# pse84 register map
Vendor: Infineon Technologies; Series: PSE84; File version: 1.0
CPU: CM33 r0p1, little endian, MPU, FPU, VTOR, 3 interrupt priority bits
Registers are 32-bit, read-write, reset 0x0 unless marked. A register's access mark holds for its fields unless they carry their own. Offsets are from the block's base; [hi:lo] are bit positions; {n}, {i} and the like mark numbered series; <NAME> marks a mode.

## CRYPTO — Cryptography component
Base 0x42440000
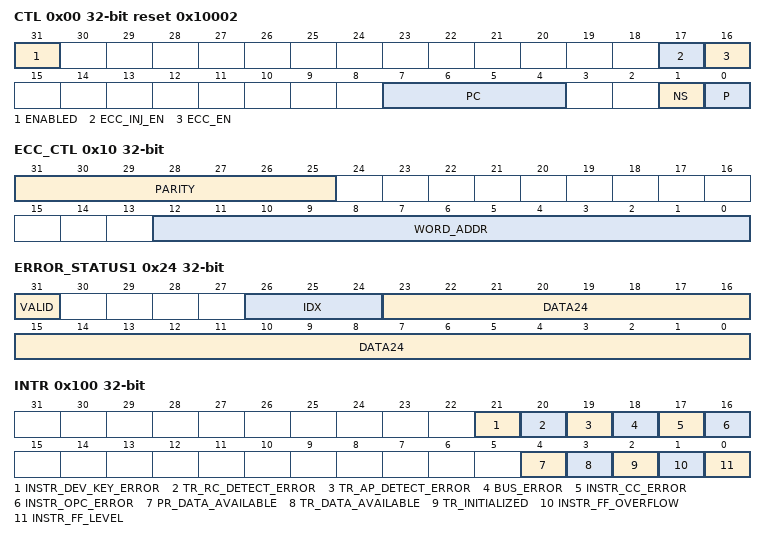
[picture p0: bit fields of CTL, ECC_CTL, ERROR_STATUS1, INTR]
0x00 CTL reset 0x10002 — Control
  [31] ENABLED — IP enable: '0': Disabled. All non-retention registers (command and status registers, instruct FIFO, internal component state machines) are reset to their default value when the IP is disabled. All retention registers retain their value when the IP is disabled. '1': Enabled. When the IP is enabled, the IP register buffer is set to '0'.
    0=DISABLED (N/A); 1=ENABLED (N/A)
  [17] ECC_INJ_EN — Enable parity injection for SRAM. When '1', the parity (ECC_CTL.PARITY) is used when a full 32-bit write is done to the ECC_CTL.WORD_ADDR word address of the SRAM.
  [16] ECC_EN — Enable ECC checking: '0': Disabled. '1': Enabled.
  [7:4] PC — Protection context. This field is set with the protection context of the transaction that writes this register; i.e. the context is inherited from the write transaction and not specified by the transaction write data. All IP master transactions use the PC field for the protection context. There is one exception: the LOAD_DEV_KEY instruction IP master transactions are always performed with protection context '0'.
  [1] NS — Secure/on-secure access control: '0': secure. '1': non-secure. This field is set with the secure/non-secure access control of the transaction that writes this register; i.e. the access control is inherited from the write transaction and not specified by the transaction write data. All IP master transactions use the NS field for the secure/non-secure access control ('hprot[4]').
  [0] P — User/privileged access control: '0': user mode. '1': privileged mode. This field is set with the user/privileged access control of the transaction that writes this register; i.e. the access control is inherited from the write transaction and not specified by the transaction write data. All IP master transactions use the P field for the user/privileged access control ('hprot[1]').
0x08 RAM_PWR_CTL reset 0x3 — SRAM power control
  [1:0] PWR_MODE — Set power mode for memory buffer SRAM.
    0=OFF (Turn OFF the SRAM. This will turn OFF both array and periphery power of the SRAM and SRAM memory contents are lost.); 1=RSVD (undefined); 2=RETAINED (Keep SRAM in Retained mode. This will turn OFF the SRAM periphery power, but array power is ON to retain memory contents. The SRAM contents will be retained in DeepSleep/DeepSleep-RAM system power mode.); 3=ENABLED (Enable SRAM for regular operation. The SRAM contents will be retained in DeepSleep/DeepSleep-RAM system power mode.)
0x0C RAM_PWR_DELAY_CTL reset 0x96 — SRAM power delay control
  [9:0] UP — Number clock cycles delay needed after power domain power up
0x10 ECC_CTL — ECC control
  [31:25] PARITY — ECC parity to use for ECC error injection at address WORD_ADDR.
  [12:0] WORD_ADDR — Specifies the word address where the parity is injected. - On a 32-bit write access to this SRAM address and when CTL.ECC_INJ_EN bit is '1', the parity (PARITY) is injected.
0x20 ERROR_STATUS0 ro reset not defined
  [31:0] DATA32 — Specifies error description information. - For INSTR_OPC_ERROR/ INSTR_CC_ERROR/ INSTR_DEV_KEY_ERROR: - Violating instruction (from instruction FIFO). - For BUS_ERROR: - Violating transfer, address.
0x24 ERROR_STATUS1 (reset mask 0x80000000)
  [31] VALID — Specifies if ERROR_STATUS0 and ERROR_STATUS1 specify valid error information. No new error information is captured as long as VALID is '1'; i.e. the error information of the first detected error is NOT overwritten.
  [26:24] IDX ro — Error source: '0': INSTR_OPC_ERROR (instruction FIFO decoder error). '1': INSTR_CC_ERROR (instruction FIFO decoder, VU CC error). '2': BUS_ERROR (bus master interface AHB-Lite bus error). '3': TR_AP_DETECT_ERROR. '4': TR_RC_DETECT_ERROR. '5': INSTR_DEV_KEY_ERROR. '6'-'7': Undefined.
  [23:0] DATA24 ro — Specifies error description information. - For BUS_ERROR: - Violating transfer, read attribute (DATA[0]). - Violating transfer, size attribute (DATA[5:4]). '0': 8-bit transfer, '1': 16 bits transfer, '2': 32-bit transfer.
0x100 INTR — Interrupt register
  [21] INSTR_DEV_KEY_ERROR — This interrupt cause is activated (HW sets the field to '1') when the LOAD_DEV_KEY instruction tries to load a device key whose DEV_KEY_ADDR_CTL.VALID or DEV_KEY_CTL.ALLOWED is set to '0'.
  [20] TR_RC_DETECT_ERROR — This interrupt cause is activated (HW sets the field to '1') when the true random number generator monitor adaptive proportion test detects a disproportionate occurrence of a specific bit value.
  [19] TR_AP_DETECT_ERROR — This interrupt cause is activated (HW sets the field to '1') when the true random number generator monitor adaptive proportion test detects a repetition of a specific bit value.
  [18] BUS_ERROR — This interrupt cause is activated (HW sets the field to '1') when a AHB-Lite bus error is observed on the AHB-Lite master interface. When the interrupt cause is activated, HW sets INSTR_FF_CTL.CLEAR to '1'.
  [17] INSTR_CC_ERROR — This interrupt cause is activated (HW sets the field to '1') when the instruction decoder encounters an instruction with a non-defined condition code. This error is only generated for VU instructions. When the interrupt cause is activated, HW sets INSTR_FF_CTL.CLEAR to '1'.
  [16] INSTR_OPC_ERROR — This interrupt cause is activated (HW sets the field to '1') when the instruction decoder encounters an instruction with a non-defined operation code (opcode). When the interrupt cause is activated, HW sets INSTR_FF_CTL.CLEAR to '1'.
  [4] PR_DATA_AVAILABLE — This interrupt cause is activated (HW sets the field to '1') when the pseudo random number generator has generated a data value.
  [3] TR_DATA_AVAILABLE — This interrupt cause is activated (HW sets the field to '1') when the true random number generator has generated a data value of the specified bit size.
  [2] TR_INITIALIZED — This interrupt cause is activated (HW sets the field to '1') when the true random number generator is initialized.
  [1] INSTR_FF_OVERFLOW — This interrupt cause is activated (HW sets the field to '1') when the instruction FIFO overflows (an attempt is made to write to a full FIFO).
  [0] INSTR_FF_LEVEL — This interrupt cause is activated (HW sets the field to '1') when the instruction FIFO event is activated.
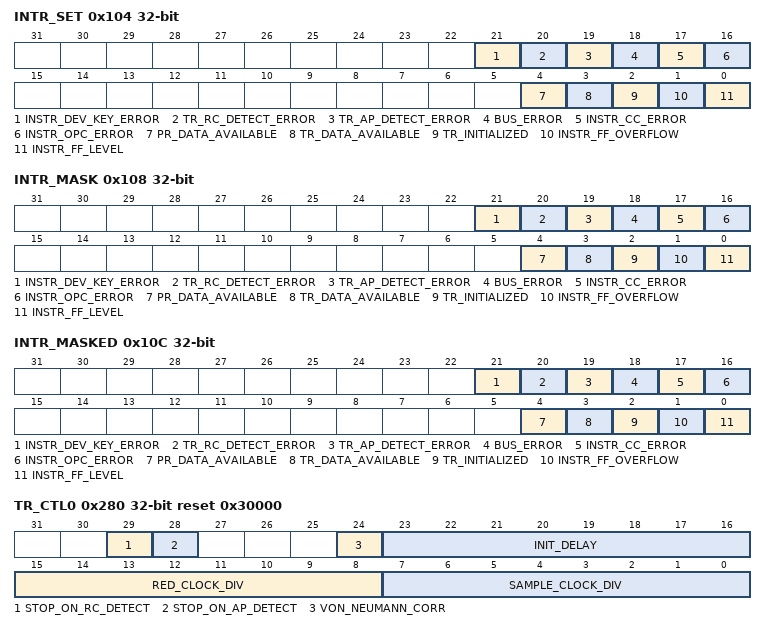
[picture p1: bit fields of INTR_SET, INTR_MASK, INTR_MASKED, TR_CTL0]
0x104 INTR_SET — Interrupt set register
  [21] INSTR_DEV_KEY_ERROR — SW writes a '1' to this field to set the corresponding field in interrupt request register.
  [20] TR_RC_DETECT_ERROR — SW writes a '1' to this field to set the corresponding field in interrupt request register.
  [19] TR_AP_DETECT_ERROR — SW writes a '1' to this field to set the corresponding field in interrupt request register.
  [18] BUS_ERROR — SW writes a '1' to this field to set the corresponding field in interrupt request register.
  [17] INSTR_CC_ERROR — SW writes a '1' to this field to set the corresponding field in interrupt request register.
  [16] INSTR_OPC_ERROR — SW writes a '1' to this field to set the corresponding field in interrupt request register.
  [4] PR_DATA_AVAILABLE — SW writes a '1' to this field to set the corresponding field in interrupt request register.
  [3] TR_DATA_AVAILABLE — SW writes a '1' to this field to set the corresponding field in interrupt request register.
  [2] TR_INITIALIZED — SW writes a '1' to this field to set the corresponding field in interrupt request register.
  [1] INSTR_FF_OVERFLOW — SW writes a '1' to this field to set the corresponding field in interrupt request register.
  [0] INSTR_FF_LEVEL — SW writes a '1' to this field to set the corresponding field in interrupt request register.
0x108 INTR_MASK — Interrupt mask register
  [21] INSTR_DEV_KEY_ERROR — Mask bit for corresponding field in interrupt request register.
  [20] TR_RC_DETECT_ERROR — Mask bit for corresponding field in interrupt request register.
  [19] TR_AP_DETECT_ERROR — Mask bit for corresponding field in interrupt request register.
  [18] BUS_ERROR — Mask bit for corresponding field in interrupt request register.
  [17] INSTR_CC_ERROR — Mask bit for corresponding field in interrupt request register.
  [16] INSTR_OPC_ERROR — Mask bit for corresponding field in interrupt request register.
  [4] PR_DATA_AVAILABLE — Mask bit for corresponding field in interrupt request register.
  [3] TR_DATA_AVAILABLE — Mask bit for corresponding field in interrupt request register.
  [2] TR_INITIALIZED — Mask bit for corresponding field in interrupt request register.
  [1] INSTR_FF_OVERFLOW — Mask bit for corresponding field in interrupt request register.
  [0] INSTR_FF_LEVEL — Mask bit for corresponding field in interrupt request register.
0x10C INTR_MASKED ro — Interrupt masked register
  [21] INSTR_DEV_KEY_ERROR — Logical and of corresponding request and mask bits.
  [20] TR_RC_DETECT_ERROR — Logical and of corresponding request and mask bits.
  [19] TR_AP_DETECT_ERROR — Logical and of corresponding request and mask bits.
  [18] BUS_ERROR — Logical and of corresponding request and mask bits.
  [17] INSTR_CC_ERROR — Logical and of corresponding request and mask bits.
  [16] INSTR_OPC_ERROR — Logical and of corresponding request and mask bits.
  [4] PR_DATA_AVAILABLE — Logical and of corresponding request and mask bits.
  [3] TR_DATA_AVAILABLE — Logical and of corresponding request and mask bits.
  [2] TR_INITIALIZED — Logical and of corresponding request and mask bits.
  [1] INSTR_FF_OVERFLOW — Logical and of corresponding request and mask bits.
  [0] INSTR_FF_LEVEL — Logical and of corresponding request and mask bits.
0x200 PR_LFSR_CTL0 reset 0xD8959BC9 — Pseudo random LFSR control 0
  [31:0] LFSR32 — State of a 32-bit Linear Feedback Shift Registers (LFSR) that is used to generate a pseudo random bit sequence. This register needs to be initialized by SW. The initialization value should be different from '0'. The three PR_LFSR_CTL registers represents the state of a 32-bit, 31-bit and 29-bit LFSR. Individually, these LFSRs generate a pseudo random bit sequence that repeats itself after (2^32)-1, (2^31)-1 and (2^29)-1 bits. The numbers (2^32)-1, (2^31)-1 and (2^29)-1 are relatively prime (their greatest common denominator is '1'). The three bit sequence are combined (XOR'd) into a single bitstream to create a pseudo random bit sequence that repeats itself after ((2^32)-1) * ((2^31)-1) * ((2*29)-1) bits. The following polynomials are used: - 32-bit irreducible polynomial: x^32+x^30+x^26+x^25+1. - 31-bit irreducible polynomial: x^31+x^28+1. - 29-bit irreducible polynomial: x^29+x^27+1.
0x204 PR_LFSR_CTL1 reset 0x2BB911F8 — Pseudo random LFSR control 1
  [30:0] LFSR31 — State of a 31-bit Linear Feedback Shift Registers (LFSR) that is used to generate a pseudo random bit sequence. See PR_LFSR_CTL0.
0x208 PR_LFSR_CTL2 reset 0x60C31B7 — Pseudo random LFSR control 2
  [28:0] LFSR29 — State of a 29-bit Linear Feedback Shift Registers (LFSR) that is used to generate a pseudo random bit sequence. See PR_LFSR_CTL0.
0x20C PR_MAX_CTL reset 0xFFFFFFFF — Pseudo random maximum control
  [31:0] DATA32 — Maximum value of to be generated random number
0x210 PR_CMD — Pseudo random command
  [0] START — Pseudo random command. On a generated number, HW sets this field to '0' and sets INTR.PR_DATA_AVAILABLE to '1.
0x218 PR_RESULT — Pseudo random result
  [31:0] DATA32 — Result of a pseudo random number generation operation. The resulting value DATA is in the range [0, PR_MAX_CTL.DATA32]. The PR_DATA_AVAILABLE interrupt cause is activated when the number is generated. Note that SW can write this field. This functionality can be used prevent information leakage.
0x280 TR_CTL0 reset 0x30000 — True random control 0
  [29] STOP_ON_RC_DETECT — Specifies if TRNG functionality is stopped on a repetition count test detection (when HW sets INTR.TR_RC_DETECT to '1'): '0': Functionality is NOT stopped. '1': Functionality is stopped (TR_CTL1 fields are set to '0' by HW).
  [28] STOP_ON_AP_DETECT — Specifies if TRNG functionality is stopped on an adaptive proportion test detection (when HW sets INTR.TR_AP_DETECT to '1'): '0': Functionality is NOT stopped. '1': Functionality is stopped (TR_CTL1 fields are set to '0' by HW).
  [24] VON_NEUMANN_CORR — Specifies if the 'von Neumann corrector' is disabled or enabled: '0': disabled. '1': enabled. The 'von Neumann corrector' post-processes the reduced bits to remove a '0' or '1' bias. The corrector operates on reduced bit pairs ('oldest bit, newest bit'): '00': no bit is produced. '01': '0' bit is produced (oldest bit). '10': '1' bit is produced (oldest bit). '11': no bit is produced. Note that the corrector produces bits at a random pace and at a frequency that is 1/4 of the reduced bit frequency (reduced bits are processed in pairs, and half of the pairs do NOT produce a bit).
  [23:16] INIT_DELAY — Specifies an initialization delay: number of removed/dropped samples before reduced bits are generated. This field should be programmed in the range [1, 255]. After starting the oscillators, at least the first 2 samples should be removed/dropped to clear the state of internal synchronizers. In addition, it is advised to drop at least the second 2 samples from the oscillators (to circumvent the semi-predictable oscillator startup behavior). This result in the default field value of '3'. Field encoding is as follows: '0': 1 sample is dropped. '1': 2 samples are dropped. ... '255': 256 samples are dropped. The TR_INITIALIZED interrupt cause is set to '1', when the initialization delay is passed.
  [15:8] RED_CLOCK_DIV — Specifies the clock divider that is used to produce reduced bits. '0': 1 reduced bit is produced for each sample. '1': 1 reduced bit is produced for each 2 samples. ... '255': 1 reduced bit is produced for each 256 samples. The reduced bits are considered random bits and shifted into TR_RESULT0.DATA32.
  [7:0] SAMPLE_CLOCK_DIV — Specifies the clock divider that is used to sample oscillator data. This clock divider is wrt. 'clk_sys'. '0': sample clock is 'clk_sys'. '1': sample clock is 'clk_sys'/2. ... '255': sample clock is 'clk_sys'/256.
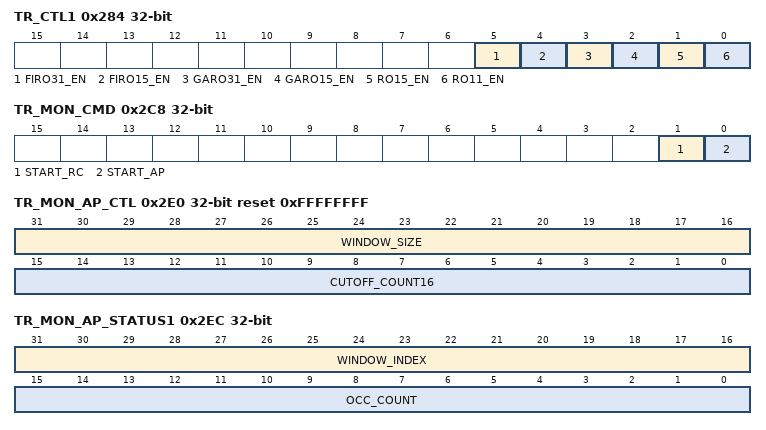
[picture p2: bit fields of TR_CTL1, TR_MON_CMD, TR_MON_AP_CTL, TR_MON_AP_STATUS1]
0x284 TR_CTL1 — True random control 1
  [5] FIRO31_EN — FW sets this field to '1' to enable the programmable Fibonacci ring oscillator with up to 31 inverters. The TR_FIRO_CTL register specifies the programmable polynomial.
  [4] FIRO15_EN — FW sets this field to '1' to enable the fixed Fibonacci ring oscillator with 15 inverters.
  [3] GARO31_EN — FW sets this field to '1' to enable the programmable Galois ring oscillator with up to 31 inverters. The TR_GARO_CTL register specifies the programmable polynomial.
  [2] GARO15_EN — FW sets this field to '1' to enable the fixed Galois ring oscillator with 15 inverters.
  [1] RO15_EN — FW sets this field to '1' to enable the ring oscillator with 15 inverters.
  [0] RO11_EN — FW sets this field to '1' to enable the ring oscillator with 11 inverters.
0x288 TR_CTL2 — True random control 2
  [5:0] SIZE — Bit size of generated random number in TR_RESULT. Legal range is in [0, 32].
0x28C TR_STATUS ro — True random status
  [0] INITIALIZED — Reflects the state of the true random number generator: '0': Not initialized (TR_CTL0.INIT_DELAY has NOT passed). '1': Initialized (TR_CTL0.INIT_DELAY has passed).
0x290 TR_CMD — True random command
  [0] START — True random command. On completion of the command, HW sets this field to '0' and sets INTR.TR_DATA_AVAILABLE to '1 when: - A random number is generated in TR_RESULT. - All ring oscillators are off (per TR_CTL1). - A repetition count (RC) or adaptive proportion (AP) error is detected during the random number generation (INTR.TR_RC/AP_DETECT_ERROR). Note: On completion of the command, SW should check TR_CTL1 and INTR.TR_RC/AP_DETECT_ERROR to ensure that no unexpected error occurred during random number generation.
0x298 TR_RESULT — True random result
  [31:0] DATA32 — Generated true random number. HW generates the number in the least significant bit positions (TR_CTL2.SIZE) of this field. The TR_DATA_AVAILABLE interrupt cause is activated when the number is generated. Note that SW can write this field. This functionality can be used prevent information leakage.
0x2A0 TR_GARO_CTL — True random GARO control
  [30:0] POLYNOMIAL31 — Polynomial for programmable Galois ring oscillator. The polynomial is represented WITHOUT the high order bit (this bit is always assumed '1'). The polynomial should be aligned such that the more significant bits (bit 30 and down) contain the polynomial and the less significant bits (bit 0 and up) contain padding '0's.
0x2A4 TR_FIRO_CTL — True random FIRO control
  [30:0] POLYNOMIAL31 — Polynomial for programmable Fibonacci ring oscillator. The polynomial is represented WITHOUT the high order bit (this bit is always assumed '1'). The polynomial should be aligned such that the more significant bits (bit 30 and down) contain the polynomial and the less significant bits (bit 0 and up) contain padding '0's.
0x2C0 TR_MON_CTL reset 0x2 — True random monitor control
  [1:0] BITSTREAM_SEL — Selection of the bitstream: '0': DAS bitstream. '1': RED bitstream. '2': TR bitstream. '3': Undefined.
0x2C8 TR_MON_CMD — True random monitor command
  [1] START_RC — Repetition count (RC) test enable: '0': Disabled. '1': Enabled. On a RC detection, HW sets this field to '0' and sets INTR.TR_RC_DETECT to '1.
  [0] START_AP — Adaptive proportion (AP) test enable: '0': Stopped. '1': Started. On a AP detection, HW sets this field to '0' and sets INTR.TR_AP_DETECT to '1.
0x2D0 TR_MON_RC_CTL reset 0xFF — True random monitor RC control
  [7:0] CUTOFF_COUNT8 — Cutoff count (legal range is [1, 255]): '0': Illegal. '1': 1 repetition. ... '255': 255 repetitions.
0x2D8 TR_MON_RC_STATUS0 ro — True random monitor RC status 0
  [0] BIT — Current active bit value: '0': '0'. '1': '1'. This field is only valid when TR_MON_RC_STATUS1.REP_COUNT is NOT equal to '0'.
0x2DC TR_MON_RC_STATUS1 ro — True random monitor RC status 1
  [7:0] REP_COUNT — Number of repetitions of the current active bit counter: '0': 0 repetitions. ... '255': 255 repetitions.
0x2E0 TR_MON_AP_CTL reset 0xFFFFFFFF — True random monitor AP control
  [31:16] WINDOW_SIZE — Window size (minus 1) : '0': 1 bit. ... '65535': 65536 bits.
  [15:0] CUTOFF_COUNT16 — Cutoff count (legal range is [1, 65535]). '0': Illegal. '1': 1 occurrence. ... '65535': 65535 occurrences.
0x2E8 TR_MON_AP_STATUS0 ro — True random monitor AP status 0
  [0] BIT — Current active bit value: '0': '0'. '1': '1'. This field is only valid when TR_MON_AP_STATUS1.OCC_COUNT is NOT equal to '0'.
0x2EC TR_MON_AP_STATUS1 ro — True random monitor AP status 1
  [31:16] WINDOW_INDEX — Counter to keep track of the current index in the window (counts from '0' to TR_MON_AP_CTL.WINDOW_SIZE to '0').
  [15:0] OCC_COUNT — Number of occurrences of the current active bit counter: '0': 0 occurrences ... '65535': 65535 occurrences
0x1004 STATUS ro
  [31] BUSY — Reflects the state of the IP: '0': Idle/no busy. '1': Busy: - Instruction is pending in the instruction FIFO. - Instruction is busy in a IP component (e.g. SHA1, SHA2, SHA3, DES, TDES, AES, CHACHA, ...). - Store FIFO is busy. - TR or PR command is busy.
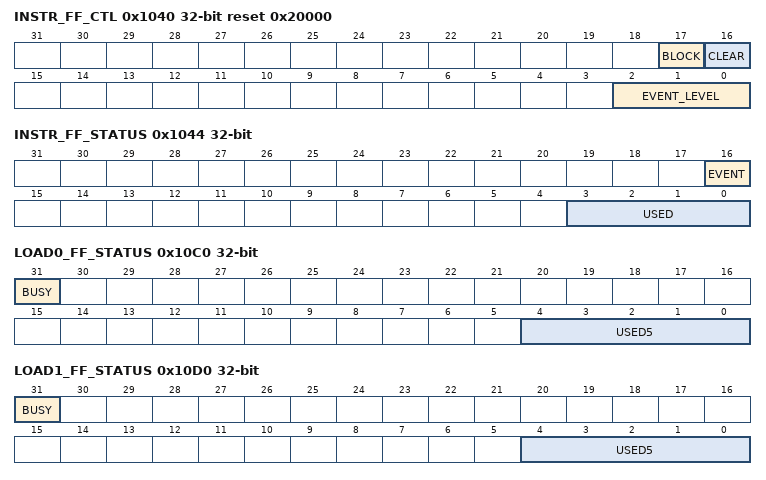
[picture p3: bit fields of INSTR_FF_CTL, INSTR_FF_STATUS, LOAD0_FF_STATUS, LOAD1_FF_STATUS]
0x1040 INSTR_FF_CTL reset 0x20000 — Instruction FIFO control
  [17] BLOCK — This field specifies the behavior when an instruction is written to a full FIFO (INSTR_FIFO_WR MMIO register): '0': The write is ignored/dropped and the INTR.INSTR_FF_OVERFLOW interrupt cause is set to '1'. '1': The write is blocked, resulting in AHB-Lite wait states and the INTR.INSTR_FF_OVERFLOW interrupt cause is set to '1' (this cause may be masked out). The instruction is written to the FIFO as soon as a FIFO entry becomes available. The maximum time is roughly the time of the execution of the slowest/longest instruction. Note that this setting may 'lock up' /stall the CPU. When the CPU is 'locked up'/stalled it can not respond to any system interrupts. As a result, the interrupt latency is increased. Note that this may not be an issue if the associated CPU is only performing cryptography functionality, e.g. the CM0+ during boot time.
  [16] CLEAR — When '1', the instruction FIFO is cleared/invalidated. Invalidation will last for as long as this field is '1'. If a quick clear/invalidation is required, the field should be set to '1' and be followed by a set to '0'. If a clear/invalidation is required for an extended time period, the field should be set to '1' during the complete time period. HW sets this field to '1' on when a INSTR_OPC_ERROR, INSTR_CC_ERROR or BUS_ERROR interrupt cause is activated.
  [2:0] EVENT_LEVEL — Event level. When the number of entries in the instruction FIFO is less than the amount of this field, an event is generated: - 'event' = INSTR_FF_STATUS.USED < EVENT_LEVEL.
0x1044 INSTR_FF_STATUS ro — Instruction FIFO status
  [16] EVENT — Instruction FIFO event.
  [3:0] USED — Number of instructions in the instruction FIFO. The value of this field ranges from 0 to 8.
0x1048 INSTR_FF_WR wo — Instruction FIFO write
  [31:0] DATA32 — Instruction or instruction operand data that is written to the instruction FIFO.
0x10C0 LOAD0_FF_STATUS ro — Load 0 FIFO status
  [31] BUSY — Reflects the state of the FIFO: '0': FIFO load engine is idle and a new FIFO instruction can be accepted. '1': FIFO load engine is busy and NO new FIFO instruction can be accepted.
  [4:0] USED5 — Number of Bytes in the FIFO. The value of this field is in the range [0, 19].
0x10D0 LOAD1_FF_STATUS ro — Load 1 FIFO status
  [31] BUSY — See LOAD1_FF_STATUS.BUSY.
  [4:0] USED5 — See LOAD1_FF_STATUS.USED.
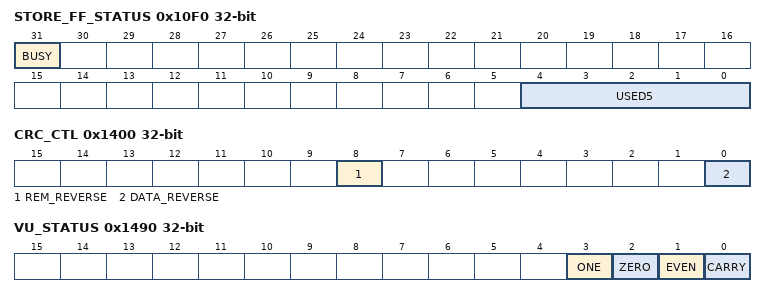
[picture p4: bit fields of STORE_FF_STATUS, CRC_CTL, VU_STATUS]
0x10F0 STORE_FF_STATUS ro — Store FIFO status
  [31] BUSY — Reflects the state of the FIFO: '0': FIFO store engine is idle and a new FIFO instruction can be accepted (USED is '0'). '1': FIFO store engine is busy and NO new FIFO instruction can be accepted.
  [4:0] USED5 — Number of Bytes in the FIFO. The value of this field is in the range [0, 16].
0x1100 AES_CTL — AES control
  [1:0] KEY_SIZE — AES key size: '0': 128-bit key, 10 rounds AES (inverse) cipher operation. '1': 192-bit key, 12 rounds AES (inverse) cipher operation. '2': 256-bit key, 14 rounds AES (inverse) cipher operation. '3': Undefined
    0=AES128 (N/A); 1=AES192 (N/A); 2=AES256 (N/A)
0x1180 RESULT
  [31:0] DATA — BLOCK_CMP operation (DATA[0]): '0': source 0 equals source 1. '1': source 0 does NOT equal source 1. CRC operation (DATA[31:0]). State of a 32-bit Linear Feedback Shift Registers (LFSR) that is used to implement CRC. This register needs to be initialized by SW to provide the CRC seed value. The seed value should be aligned such that the more significant bits (bit 31 and down) contain the seed value and the less significant bits (bit 0 and up) contain padding '0's. Note that SW can write this field. This functionality can be used prevent information leakage.
0x1400 CRC_CTL — CRC control
  [8] REM_REVERSE — Specifies whether the remainder is bit reversed (reversal is performed after XORing): '0': No. '1': Yes.
  [0] DATA_REVERSE — Specifies the bit order in which a data Byte is processed (reversal is performed after XORing): '0': Most significant bit (bit 1) first. '1': Least significant bit (bit 0) first.
0x1410 CRC_DATA_CTL — CRC data control
  [7:0] DATA_XOR — Specifies a byte mask with which each data byte is XOR'd. The XOR is performed before data reversal.
0x1420 CRC_POL_CTL — CRC polynomial control
  [31:0] POLYNOMIAL — CRC polynomial. The polynomial is represented WITHOUT the high order bit (this bit is always assumed '1'). The polynomial should be aligned/shifted such that the more significant bits (bit 31 and down) contain the polynomial and the less significant bits (bit 0 and up) contain padding '0's. Some frequently used polynomials: - CRC32: POLYNOMIAL is 0x04c11db7 (x^32 + x^26 + x^23 + x^22 + x^16 + x^12 + x^11 + x^10 + x^8 + x^7 + x^5 + x^4 + x^2 + x + 1). - CRC16: POLYNOMIAL is 0x80050000 (x^16 + x^15 + x^2 + 1, shifted by 16 bit positions). - CRC16 CCITT: POLYNOMIAL is 0x10210000 (x^16 + x^12 + x^5 + 1, shifted by 16 bit positions).
0x1440 CRC_REM_CTL — CRC remainder control
  [31:0] REM_XOR — Specifies a mask with which the CRC_LFSR_CTL.LFSR32 register is XOR'd to produce a remainder. The XOR is performed before remainder reversal.
0x1448 CRC_REM_RESULT ro — CRC remainder result
  [31:0] REM — Remainder value. The alignment of the remainder depends on CRC_REM_CTL0.REM_REVERSE: '0': the more significant bits (bit 31 and down) contain the remainder. '1': the less significant bits (bit 0 and up) contain the remainder. Note: This field is combinatorially derived from CRC_LFSR_CTL.LFSR32, CRC_REM_CTL0.REM_REVERSE and CRC_REM_CTL1.REM_XOR.
0x1480 VU_CTL0 — Vector unit control 0
  [0] ALWAYS_EXECUTE — Specifies if a conditional instruction is executed or not, when its condition code evaluates to false/'0'. '0': The instruction is NOT executed. As a result, the instruction may be handled faster than when it is executed. '1': The instruction is executed, but the execution result (including status field information) is not reflected in the IP. The instruction is handled just as fast as when it is executed. Note: a conditional instruction with a condition code that evaluates to false/'0' does not affect the architectural state: VU_STATUS fields, memory or register-file data. Note: Always execution is useful to prevent/complicate differential timing and differential power attacks.
0x1484 VU_CTL1 — Vector unit control 1
  [31:8] ADDR24 — Specifies the memory address for the vector unit operand memory region. The register-file registers provide 13-bit word offsets within this memory region. Given ADDR[31:8], VU_VTL2.MASK[14:8] and a 13-bit word offset offset[14:2], a vector operand memory address VU_OPERAND_ADDR[31:0] is calculated as follows: - VU_OPERAND_ADDR[31:15] = ADDR[31:15] - VU_OPERAND_ADDR[14:8] = (ADDR[14:8] & MASK[14:8]) | (offset[14:8] & ~MASK[14:8]) - VU_OPERAND_ADDR[7:2] = offset[7:2] - VU_OPERAND_ADDR[1:0] = 0 (always word aligned) The vector unit operand memory region uses either the IP's memory buffer or system memory. For best performance, the IP's memory buffer should be used and ADDR should be set to MEM_BUFF and MASK should specify the IP memory buffer size. If a vector operand memory address is mapped on a memory hole, read accesses return a '0' and write accesses are ignored Note: The base address of the IP internal memory buffer is equal to IP_ADDR + MEM_BUFF where. - IP_ADDR is the top-level design time parameter. - MEM_BUFF is address offset value for MEM_BUFF MMIO register..
0x1488 VU_CTL2 reset 0x7F00 — Vector unit control 2
  [14:8] MASK — Specifies the size of the vector operand memory region. Legal values: '0b0000000': 32 KB memory region (VU_VTL1.ADDR[14:8] ignored). '0b1000000': 16 KB memory region (VU_VTL1.ADDR[13:8] ignored). '0b1100000': 8 KB memory region (VU_VTL1.ADDR[12:8] ignored). '0b1110000': 4 KB memory region (VU_VTL1.ADDR[11:8] ignored). '0b1111000': 2 KB memory region (VU_VTL1.ADDR[10:8] ignored). '0b1111100': 1 KB memory region (VU_VTL1.ADDR[9:8] ignored). '0b1111110': 512 B memory region (VU_VTL1.ADDR[8] ignored). '0b1111111': 256 B memory region. Note: the default specifies a 256 B memory region.
0x1490 VU_STATUS ro — Vector unit status
  [3] ONE — STATUS ONE field.
  [2] ZERO — STATUS ZERO field.
  [1] EVEN — STATUS EVEN field.
  [0] CARRY — STATUS CARRY field.
{0x14C0+4i} VU_RF_DATA[{i}] (i=0..15) ro — Vector unit register-file
  [31:0] DATA32 — Vector unit register-file data. A register-file register has the following layout: DATA[28:16]: data (typically used as a word offset in vector unit operand memory). DATA[12:0]: bit size minus 1.
0x2000 DEV_KEY_ADDR0_CTL — Device key address 0 control
  [31] VALID — Specifies if the address in the associated DEV_KEY_ADDR0 is valid: '0': Address not valid; i.e. no device key specified. '1': Address valid; i.e. device key specified. Note: A LOAD_DEV_KEY instruction requires that the device key's valid field is '1'.
0x2004 DEV_KEY_ADDR0 — Device key address 0
  [31:0] ADDR32 — Specifies the memory address of the device key in memory. A LOAD_DEV_KEY instruction uses this address to load a device key from memory into the IP register buffer blocks 4 and 5.
0x2020 DEV_KEY_ADDR1_CTL — Device key address 1 control
  [31] VALID — See DEV_KEY_ADDR0_CTL.
0x2024 DEV_KEY_ADDR1 — Device key address 1 control
  [31:0] ADDR32 — See DEV_KEY_ADDR0.
0x2080 DEV_KEY_STATUS ro — Device key status
  [0] LOADED — Specifies if a device key is present in the IP register buffer blocks 4 and 5. HW sets this field to '1' on successful completion of a LOAD_DEV_KEY instruction. HW clears this field to '0' when a CLEAR instruction is executed (the CLEAR instruction also sets the IP register buffer to '0').
0x2100 DEV_KEY_CTL0 — Device key control 0
  [0] ALLOWED — Specifies if a LOAD_DEV_KEY instruction is allowed to use the device key in memory: '0': Not allowed. '1': Allowed. Note: For successful completion of a LOAD_DEV_KEY instruction, both the associated DEV_KEY_ADDR_CTL.VALID and DEV_KEY_CTL.ALLOWED fields must be '1'. On successful instruction completion, DEV_KEY_STATUS.LOADED is set to '1'. On unsuccessful completion, the instruction FIFO is cleared and the IP is locked; an Active reset or an IP reset (CTL.ENABLED), which reinitializes the IP, is required. Note: A LOAD_DEV_KEY loads the device key from memory with protection context '0'.
0x2120 DEV_KEY_CTL1 — Device key control 1
  [0] ALLOWED — See DEV_KEY_CTL0.
